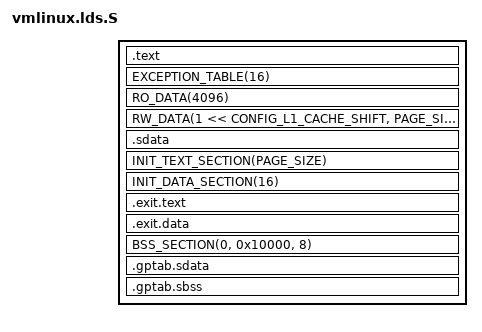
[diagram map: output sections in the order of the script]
/* SPDX-License-Identifier: GPL-2.0 */
#include <asm/asm-offsets.h>
#include <asm/thread_info.h>

#define PAGE_SIZE _PAGE_SIZE

/*
 * Put .bss..swapper_pg_dir as the first thing in .bss. This will
 * ensure that it has .bss alignment (64K).
 */
#define BSS_FIRST_SECTIONS *(.bss..swapper_pg_dir)

#include <asm-generic/vmlinux.lds.h>

OUTPUT_ARCH(loongarch)
ENTRY(kernel_entry)
PHDRS {
	text PT_LOAD FLAGS(7);	/* RWX */
	note PT_NOTE FLAGS(4);	/* R__ */
}

jiffies	 = jiffies_64;

SECTIONS
{
	. = VMLINUX_LOAD_ADDRESS;
	/* Read-only */
	_text = .;	/* Text and read-only data */
	.text : {
		TEXT_TEXT
		SCHED_TEXT
		CPUIDLE_TEXT
		LOCK_TEXT
		KPROBES_TEXT
		IRQENTRY_TEXT
		SOFTIRQENTRY_TEXT
		*(.fixup)
		*(.gnu.warning)
	} :text = 0
	_etext = .;	/* End of text section */

	EXCEPTION_TABLE(16)

	_sdata = .;			/* Start of data section */
	RO_DATA(4096)
	RW_DATA(1 << CONFIG_L1_CACHE_SHIFT, PAGE_SIZE, THREAD_SIZE)

	/* We want the small data sections together, so single-instruction offsets
	   can access them all, and initialized data all before uninitialized, so
	   we can shorten the on-disk segment size.  */
	.sdata : {
		*(.sdata)
	}
	_edata =  .;			/* End of data section */

	/* Will be freed after init */
	. = ALIGN(PAGE_SIZE);		/* Init code and data */
	__init_begin = .;
	INIT_TEXT_SECTION(PAGE_SIZE)
	INIT_DATA_SECTION(16)

	. = ALIGN(4);

	/* .exit.text is discarded at runtime, not link time, to deal with
	 * references from .rodata
	 */
	.exit.text : {
		EXIT_TEXT
	}
	.exit.data : {
		EXIT_DATA
	}

	/*
	 * Align to 64K in attempt to eliminate holes before the
	 * .bss..swapper_pg_dir section at the start of .bss.  This
	 * also satisfies PAGE_SIZE alignment as the largest page size
	 * allowed is 64K.
	 */
	. = ALIGN(0x10000);
	__init_end = .;
	/* freed after init ends here */

	/*
	 * Force .bss to 64K alignment so that .bss..swapper_pg_dir
	 * gets that alignment.	 .sbss should be empty, so there will be
	 * no holes after __init_end. */
	BSS_SECTION(0, 0x10000, 8)

	_end = . ;

	STABS_DEBUG
	DWARF_DEBUG

	/* These must appear regardless of  .  */
	.gptab.sdata : {
		*(.gptab.data)
		*(.gptab.sdata)
	}
	.gptab.sbss : {
		*(.gptab.bss)
		*(.gptab.sbss)
	}

	/* Sections to be discarded */
	DISCARDS
	/DISCARD/ : {
		*(.gnu.attributes)
		*(.options)
		*(.eh_frame)
	}
}
